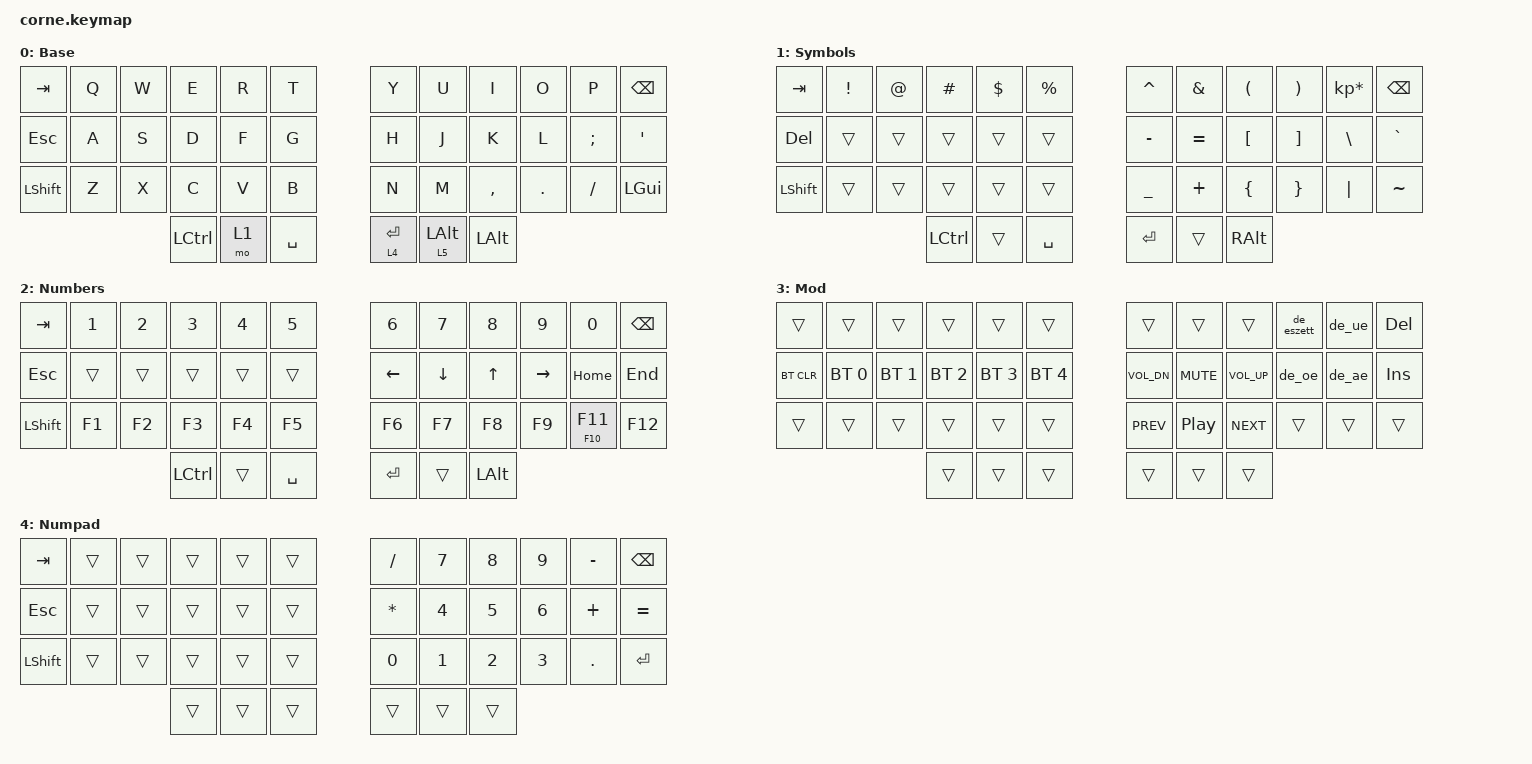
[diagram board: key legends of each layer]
/*
 * Copyright (c) 2020 The ZMK Contributors
 *
 * SPDX-License-Identifier: MIT
 */

#include <behaviors.dtsi>
#include <dt-bindings/zmk/keys.h>
#include <dt-bindings/zmk/bt.h>

/* Use macOS Unicode Hex Input. For Windows/WinCompose, remove this define or set HOST_OS to 0. */
#define HOST_OS 2
#include "../zmk-helpers/helper.h"
#include "../zmk-helpers/international_chars/german.dtsi"

/ {
        /*
         * CONDITIONAL LAYERS
         * tri_layer: When both layer 1 and 2 are active, activate layer 3
         * numpad_layer: When both layer 4 and 5 are held (right thumb keys), activate layer 6 (numpad)
         */
        conditional_layers {
            compatible = "zmk,conditional-layers";
            tri_layer {
                if-layers = <1 2>;
                then-layer = <3>;
            };
            numpad_layer {
                if-layers = <4 5>;
                then-layer = <6>;
            };
        };

        keymap {
                compatible = "zmk,keymap";

                default_layer {
// -----------------------------------------------------------------------------------------
// |  TAB |  Q  |  W  |  E   |  R  |  T  |   |  Y  |  U   |  I  |  O  |  P  | BKSP |
// |  ESC |  A  |  S  |  D   |  F  |  G  |   |  H  |  J   |  K  |  L  |  ;  |  '   |
// | SHFT |  Z  |  X  |  C   |  V  |  B  |   |  N  |  M   |  ,  |  .  |  /  | GUI  |
//                    | CTRL | LWR | SPC |   | ENT | RSE  | ALT |
                        display-name = "Base";
                        bindings = <
   &kp TAB   &kp Q &kp W &kp E &kp R &kp T   &kp Y &kp U  &kp I     &kp O   &kp P    &kp BSPC
   &kp ESC   &kp A &kp S &kp D &kp F &kp G   &kp H &kp J  &kp K     &kp L   &kp SEMI &kp SQT
   &kp LSHFT &kp Z &kp X &kp C &kp V &kp B   &kp N &kp M  &kp COMMA &kp DOT &kp FSLH &kp LGUI
                 &kp LCTRL &mo 1 &kp SPACE   &lt 4 RET &lt 5 LALT &kp LALT
                        >;
                };

                symbols_layer {
// -----------------------------------------------------------------------------------------
// |  TAB |  !  |  @  |  #   |  $  |  %  |   |  ^  |  &  |  (  |  )  |  *  | BKSP |
// |  DEL |     |     |      |     |     |   |  -  |  =  |  [  |  ]  |  \  |  `   |
// | SHFT |     |     |      |     |     |   |  _  |  +  |  {  |  }  | "|" |  ~   |
//                    | CTRL |     | SPC |   | ENT |     | RALT|
                        display-name = "Symbols";
                        bindings = <
   &kp TAB &kp EXCL &kp AT &kp HASH  &kp DLLR &kp PRCNT   &kp CARET &kp AMPS  &kp LPAR &kp RPAR &kp KP_MULTIPLY &kp BSPC
   &kp DEL &trans   &trans &trans    &trans   &trans      &kp MINUS &kp EQUAL &kp LBKT        &kp RBKT &kp BSLH &kp GRAVE
   &kp LSHFT &trans &trans &trans    &trans   &trans      &kp UNDER &kp PLUS  &kp LBRC        &kp RBRC &kp PIPE &kp TILDE
                    	     &kp LCTRL &trans   &kp SPACE   &kp RET   &trans  &kp RALT
                        >;
                };

                numbers_layer {
// -----------------------------------------------------------------------------------------
// |  TAB |  1  |  2  |  3    |  4  |  5  |   |  6  |  7  |  8  |  9  |  0   | BKSP |
// |  ESC |     |     |       |     |     |   | LFT | DWN |  UP | RGT | HOME | END  |
// | SHFT | F1  |  F2 |  F3   |  F4 | F5  |   | F6  | F7  |  F8 |  F9 | F10  | F12  |
//                    | BTCLR |     | SPC |   | ENT |     | ALT |       F11
                        display-name = "Numbers";
                        bindings = <
   &kp TAB    &kp N1       &kp N2       &kp N3       &kp N4       &kp N5         &kp N6   &kp N7   &kp N8 &kp N9    &kp N0 &kp BSPC
   &kp ESC    &trans &trans &trans &trans &trans     &kp LEFT &kp DOWN &kp UP &kp RIGHT &kp HOME  &kp END
   &kp LSHFT  &kp F1       &kp F2       &kp F3       &kp F4       &kp F5         &kp F6   &kp F7   &kp F8 &kp F9 &mt F10 F11 &kp F12
                          	        &kp LCTRL &trans &kp SPACE      &kp RET  &trans   &kp LALT
                        >;
                };

                modification_layer {
// -----------------------------------------------------------------------------------------
// |      |     |     |       |     |     |   |     |     |     |  ß  |  Ü  | DEL |
// | BTCLR| BT1 | BT2 | BT3   | BT4 | BT5 |   | VOL-| MUTE| VOL+|  Ö  |  Ä  | INS |
// |      |     |     |       |     |     |   | PREV| PLAY| NEXT|     |     |     |
//                    |       |     |     |   |     |     |     |
                        display-name = "Mod";
                        bindings = <
   &trans &trans &trans &trans &trans &trans    &trans &trans &trans &de_eszett &de_ue &kp DEL
   &bt BT_CLR &bt BT_SEL 0 &bt BT_SEL 1 &bt BT_SEL 2 &bt BT_SEL 3 &bt BT_SEL 4   &kp C_VOL_DN &kp C_MUTE &kp C_VOL_UP &de_oe &de_ae &kp INS
   &trans &trans &trans &trans &trans &trans    &kp C_PREV &kp C_PP &kp C_NEXT &trans &trans &trans
                        &trans &trans &trans    &trans &trans &trans
                        >;
                };

                numpad_layer {
// -----------------------------------------------------------------------------------------
// |  TAB |     |     |     |     |     |   |  /  |  7  |  8  |  9  |  -  | BKSP |
// |  ESC |     |     |     |     |     |   |  *  |  4  |  5  |  6  |  +  |  =   |
// | SHFT |     |     |     |     |     |   |  0  |  1  |  2  |  3  |  .  | ENT  |
//                    |     |     |     |   |     |     |     |
                        display-name = "Numpad";
                        bindings = 
   &kp TAB   &trans &trans &trans &trans &trans   &kp FSLH &kp N7 &kp N8 &kp N9 &kp MINUS &kp BSPC
   &kp ESC   &trans &trans &trans &trans &trans   &kp STAR &kp N4 &kp N5 &kp N6 &kp PLUS  &kp EQUAL
   &kp LSHFT &trans &trans &trans &trans &trans   &kp N0   &kp N1 &kp N2 &kp N3 &kp DOT   &kp RET
                           &trans &trans &trans   &trans   &trans &trans
                        >;
                };
        };
};
